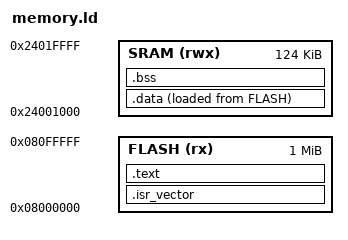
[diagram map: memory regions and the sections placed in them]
ENTRY(Reset_Handler)
MEMORY {
  FLASH (rx) : ORIGIN = 0x08000000, LENGTH = 1M
  SRAM (rwx) : ORIGIN = 0x24001000, LENGTH = 0x1F000
}
_estack = 0x24020000;
SECTIONS {
  .isr_vector : { KEEP(*(.isr_vector)) } > FLASH
  .text : { *(.text*) *(.rodata*) } > FLASH
  . = ALIGN(4);
  _sidata = LOADADDR(.data);
  .data : {
    _sdata = .;
    *(.data*)
    . = ALIGN(4);
    _edata = .;
  } > SRAM AT > FLASH
  .bss (NOLOAD) : {
    . = ALIGN(4);
    _sbss = .;
    *(.bss*) *(COMMON)
    . = ALIGN(4);
    _ebss = .;
  } > SRAM
}
ASSERT(_ebss < _estack - 0x1000, "insufficient stack headroom")
